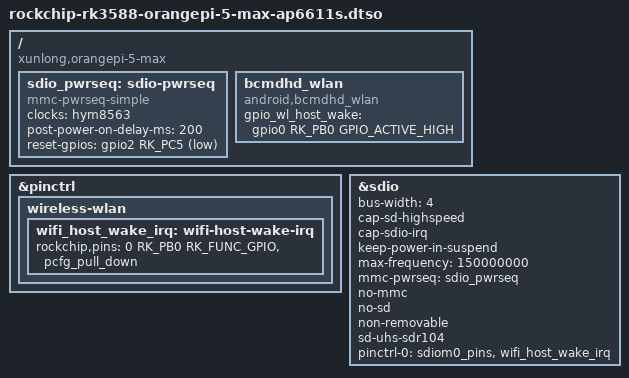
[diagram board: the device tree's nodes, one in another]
// SPDX-License-Identifier: (GPL-2.0+ OR MIT)
/*
 * Orange Pi 5 Max: onboard AP6611S (Synaptics SYN43711) WiFi on SDIO,
 * driven by bcmdhd-sdio-dkms built with CONFIG_BCMDHD_DTS.
 *
 * WL_REG_ON     GPIO2_C5, power sequence reset, active low
 * WL_HOST_WAKE  GPIO0_B0, out-of-band interrupt, active high
 * LPO 32.768k   hym8563 clock output, shared with Bluetooth
 * SDIO pins     sdiom0 (the SoC default for &sdio is sdiom1)
 */

/dts-v1/;
/plugin/;

#include <dt-bindings/gpio/gpio.h>
#include <dt-bindings/pinctrl/rockchip.h>

/ {
	compatible = "xunlong,orangepi-5-max", "rockchip,rk3588";

	fragment@0 {
		target-path = "/";

		__overlay__ {
			sdio_pwrseq: sdio-pwrseq {
				compatible = "mmc-pwrseq-simple";
				clocks = <&hym8563>;
				clock-names = "ext_clock";
				post-power-on-delay-ms = <200>;
				reset-gpios = <&gpio2 RK_PC5 GPIO_ACTIVE_LOW>;
			};

			/* read by bcmdhd; WL_REG_ON stays with sdio_pwrseq */
			bcmdhd_wlan {
				compatible = "android,bcmdhd_wlan";
				gpio_wl_host_wake = <&gpio0 RK_PB0 GPIO_ACTIVE_HIGH>;
			};
		};
	};

	fragment@1 {
		target = <&pinctrl>;

		__overlay__ {
			wireless-wlan {
				wifi_host_wake_irq: wifi-host-wake-irq {
					rockchip,pins = <0 RK_PB0 RK_FUNC_GPIO &pcfg_pull_down>;
				};
			};
		};
	};

	fragment@2 {
		target = <&sdio>;

		__overlay__ {
			bus-width = <4>;
			cap-sd-highspeed;
			cap-sdio-irq;
			keep-power-in-suspend;
			max-frequency = <150000000>;
			mmc-pwrseq = <&sdio_pwrseq>;
			no-mmc;
			no-sd;
			non-removable;
			sd-uhs-sdr104;
			pinctrl-names = "default";
			pinctrl-0 = <&sdiom0_pins>, <&wifi_host_wake_irq>;
			status = "okay";
		};
	};
};
